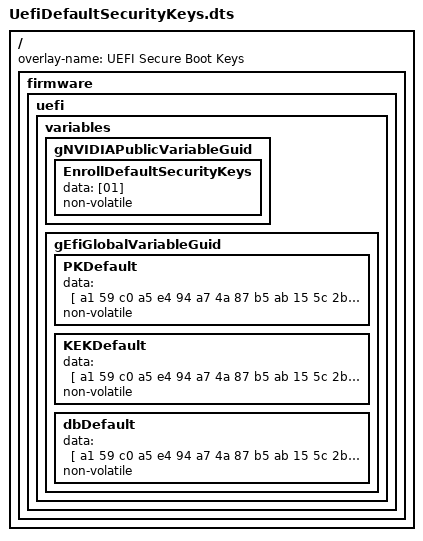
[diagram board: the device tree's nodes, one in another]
/** @file
*
*  Copyright (c) 2023, NVIDIA CORPORATION & AFFILIATES. All rights reserved.
*
*  SPDX-License-Identifier: BSD-2-Clause-Patent
*
**/
/dts-v1/;
/plugin/;
/ {
    overlay-name = "UEFI Secure Boot Keys";
    fragment@0 {
        target-path = "/";
        board_config {
            sw-modules = "uefi";
        };
        __overlay__ {
            firmware {
                uefi {
                    variables {
                        gNVIDIAPublicVariableGuid {
                            EnrollDefaultSecurityKeys {
                                data = [01];
                                non-volatile;
                            };
                        };
                        gEfiGlobalVariableGuid {
                            PKDefault {
                                data = [
 a1 59 c0 a5 e4 94 a7 4a 87 b5 ab 15 5c 2b f0 72
 45 03 00 00 00 00 00 00 29 03 00 00 7a 8a f5 48
 32 b1 61 4e b8 34 e8 10 be 6f e1 2a 30 82 03 15
 30 82 01 fd a0 03 02 01 02 02 14 2b 3d d5 c5 00
 8a cb 62 a8 bc d1 e1 d6 67 f1 09 9d 78 b3 18 30
 0d 06 09 2a 86 48 86 f7 0d 01 01 0b 05 00 30 1a
 31 18 30 16 06 03 55 04 03 0c 0f 6d 79 20 50 6c
 61 74 66 6f 72 6d 20 4b 65 79 30 1e 17 0d 32 33
 30 39 31 39 32 30 35 31 34 38 5a 17 0d 33 33 30
 39 31 36 32 30 35 31 34 38 5a 30 1a 31 18 30 16
 06 03 55 04 03 0c 0f 6d 79 20 50 6c 61 74 66 6f
 72 6d 20 4b 65 79 30 82 01 22 30 0d 06 09 2a 86
 48 86 f7 0d 01 01 01 05 00 03 82 01 0f 00 30 82
 01 0a 02 82 01 01 00 b8 79 e8 a8 e0 42 ee 26 be
 7a df 9b 87 3b b6 f8 f2 cd 36 02 a3 3a d9 23 ba
 ba f2 52 91 be f3 2a f1 0f 71 1d 7d 46 b3 04 74
 59 a1 51 f4 53 31 ed 18 a8 3c cb eb 56 ca fb f5
 d8 f0 91 c1 9a 37 0f 99 08 bd ad 8c ee de c8 8c
 e4 e7 a0 51 b3 85 06 6f e7 32 cb 68 ca dd db 16
 24 1a 8f 71 2c 3f a0 fe 41 db 8b 65 5b dd 6d 68
 bc 57 8b 59 00 53 9a 30 fe a2 a9 23 4b f4 0b ab
 7e 2d 8a d0 83 87 28 c2 e5 de 07 41 b1 c3 ed 2f
 98 f7 f1 1c c7 fb 7d 6d 19 54 96 27 36 85 5b f8
 26 37 c3 b7 4f 68 7d 4d 83 48 3e 27 61 a4 8c e9
 33 89 6f d7 a7 e6 cc 14 e3 1a f4 7d 3d 22 8d ff
 a4 14 64 24 2a 30 6d 94 dc b6 0e 99 06 8c a0 2e
 32 0b ee 63 60 92 d6 89 ce 74 a4 6d bc f8 fa 94
 f8 d7 3e 15 ea 50 35 83 37 d3 68 cd fc 5e 85 53
 bb db d8 11 a8 2c be 64 32 ab 99 8e 90 99 e8 04
 12 fe 33 1d 57 61 21 02 03 01 00 01 a3 53 30 51
 30 1d 06 03 55 1d 0e 04 16 04 14 6f 55 55 a2 58
 c7 90 6b 9c 11 bf f0 f3 10 81 12 18 0c 0c 62 30
 1f 06 03 55 1d 23 04 18 30 16 80 14 6f 55 55 a2
 58 c7 90 6b 9c 11 bf f0 f3 10 81 12 18 0c 0c 62
 30 0f 06 03 55 1d 13 01 01 ff 04 05 30 03 01 01
 ff 30 0d 06 09 2a 86 48 86 f7 0d 01 01 0b 05 00
 03 82 01 01 00 74 d7 ce 48 a0 67 06 7c 07 03 4b
 d1 d1 30 74 e7 17 76 3b 1d 89 36 88 9c c4 01 f9
 28 63 06 bc 92 ba ad 69 2f 27 46 e0 90 a3 c5 62
 29 96 d8 92 23 2f 9e 80 51 e5 22 3e f1 d0 99 18
 48 5d fc 95 20 57 da b0 d8 13 c4 58 b4 51 ed f4
 90 6d f9 41 8a b7 a6 a4 92 f7 bc d3 ec 65 0c 16
 fc 85 ed 46 dc 69 82 8e 65 0c b6 f6 0e 54 dd e1
 4b a1 c0 68 64 aa 1a 3d d1 01 d9 2d 7c 6f ac 7f
 f5 c5 01 8b 8b 51 6d b0 a7 15 4d a9 d1 72 16 86
 24 43 20 3d aa 16 25 6d a8 a1 2f 41 17 59 47 7f
 db 68 fe 4b 0f 4f dd 9c 9d 9c fc 69 5c 20 11 2a
 dd be 03 36 17 bb 4c 4d 41 57 e8 9b 7a dc b3 85
 8e 1e 51 3b c0 f8 1e ea d6 52 df 91 ce 77 a9 a6
 43 42 87 be 41 0d f0 89 1f 1e cd 1a df 10 04 0e
 c8 10 dd b5 19 61 3d 01 1d 08 22 03 55 e4 8a ae
 77 ee dc 50 df 05 53 da 57 4a b6 29 cc fd df 11
 84 0b dd 2f ea
                                ];
                                non-volatile;
                            };
                            KEKDefault {
                                data = [
 a1 59 c0 a5 e4 94 a7 4a 87 b5 ab 15 5c 2b f0 72
 4d 03 00 00 00 00 00 00 31 03 00 00 4b 3b d9 b0
 e3 95 4b 45 86 fe 99 7f d9 d6 bf 01 30 82 03 1d
 30 82 02 05 a0 03 02 01 02 02 14 2a b7 23 c1 01
 94 4d 45 ce 40 ed 71 28 7d 0d dd 45 dc ee ab 30
 0d 06 09 2a 86 48 86 f7 0d 01 01 0b 05 00 30 1e
 31 1c 30 1a 06 03 55 04 03 0c 13 6d 79 20 4b 65
 79 20 45 78 63 68 61 6e 67 65 20 4b 65 79 30 1e
 17 0d 32 33 30 39 31 39 32 30 35 32 31 30 5a 17
 0d 33 33 30 39 31 36 32 30 35 32 31 30 5a 30 1e
 31 1c 30 1a 06 03 55 04 03 0c 13 6d 79 20 4b 65
 79 20 45 78 63 68 61 6e 67 65 20 4b 65 79 30 82
 01 22 30 0d 06 09 2a 86 48 86 f7 0d 01 01 01 05
 00 03 82 01 0f 00 30 82 01 0a 02 82 01 01 00 9a
 2a a1 86 9c 96 8f fb 86 10 bd b2 54 d7 0c 23 b3
 59 64 96 f2 a3 29 bd f0 36 b8 a6 fe 1e aa a3 9d
 04 d4 69 08 76 b6 99 63 1b f9 1a 92 6d 55 6c 46
 d5 06 e3 a7 d6 be 4b d8 a9 9e 86 1c 78 c1 ba 2d
 9a 4a 29 2b a1 7b 80 92 86 9e 76 c2 1b 7c a7 33
 3c 44 c9 65 f1 40 9f 35 94 9a ec e7 de ea 60 8e
 3d 74 01 00 07 e9 6a a0 90 2e ed a7 45 66 5c 19
 16 7c 77 a0 c1 2c 87 39 2e 70 8c 25 26 1f 95 52
 5f 11 c9 9b 18 d2 02 88 2c 67 cf b2 b9 01 4c 33
 a2 73 24 5d ee 97 a1 12 37 40 05 18 f6 0a 74 de
 41 13 3d f8 7f a3 1e c5 65 f1 0f 6c 43 de d6 ee
 0c 91 87 db c7 da 1b e7 ed 87 67 ed f3 bc d9 c7
 ca 1c 8f b0 83 48 ff f6 f0 40 bc 44 cd fb 45 52
 89 ff a8 53 33 79 b3 2e 4a 3f b2 ff f3 bc 8d 92
 8b f3 8b 19 d5 cf 70 11 1b ce c0 c3 74 57 4b 6f
 5d 9a be 09 e0 0c 5d 44 c1 20 95 d8 40 69 eb 02
 03 01 00 01 a3 53 30 51 30 1d 06 03 55 1d 0e 04
 16 04 14 ea 25 0e 39 55 31 b1 db e6 e9 25 7f 73
 e2 bc fc 1d bc 4f c3 30 1f 06 03 55 1d 23 04 18
 30 16 80 14 ea 25 0e 39 55 31 b1 db e6 e9 25 7f
 73 e2 bc fc 1d bc 4f c3 30 0f 06 03 55 1d 13 01
 01 ff 04 05 30 03 01 01 ff 30 0d 06 09 2a 86 48
 86 f7 0d 01 01 0b 05 00 03 82 01 01 00 42 67 ca
 59 4d 62 d1 39 4f d8 93 c1 09 b8 9c 29 a1 1c bc
 ae 82 26 9e d5 dd 35 f6 12 47 47 2b fb 5d 0b 4d
 e8 0c 4c c9 70 b9 85 e5 81 4f 9f 71 00 70 fe 55
 1b ee 47 f7 fa 41 77 ed 58 d1 16 ac 1f 44 a3 03
 f2 47 c5 db 1d 96 fa de 01 a4 34 0f 3e 1d 4e 90
 d6 50 4d 5e 85 cb 09 7b 69 c4 7c b0 cd 78 26 00
 f0 55 78 09 c1 5d cd 8d bd ce 61 a9 db 7d da a1
 6f 6e b6 58 d9 b9 00 c0 d4 90 6f 9e ea 94 d6 17
 0e 05 1a 16 46 26 e0 10 8c 62 f5 3f c3 96 b1 d4
 37 c0 c3 e6 d4 53 10 4b a8 c1 96 41 94 d2 24 0e
 24 d3 e9 9d 58 7d df 04 18 25 e7 66 aa 91 43 50
 b1 d8 48 2c b4 69 d6 8d 6a ab 81 ab 52 2d 19 b3
 2a c7 86 f6 87 66 40 69 ad 58 60 08 0a c9 f0 8b
 eb 91 04 55 13 d8 92 00 1e 1c 8b 13 0d 9a 71 32
 c4 e4 d0 e2 3c ee d2 50 7f e4 93 4d ef ed 8f 53
 8a 7f d0 3d bf 37 4a 66 26 da 4d 6a 79
                                ];
                                non-volatile;
                            };
                            dbDefault {
                                data = [
 a1 59 c0 a5 e4 94 a7 4a 87 b5 ab 15 5c 2b f0 72
 59 03 00 00 00 00 00 00 3d 03 00 00 50 7c ee b0
 ed 19 f9 4e 95 4a 86 1f d2 57 b1 a3 30 82 03 29
 30 82 02 11 a0 03 02 01 02 02 14 78 9b c4 26 ce
 38 9a 5b 80 0d d0 3b 28 e0 c2 ef 05 cb 37 59 30
 0d 06 09 2a 86 48 86 f7 0d 01 01 0b 05 00 30 24
 31 22 30 20 06 03 55 04 03 0c 19 6d 79 20 53 69
 67 6e 61 74 75 72 65 20 44 61 74 61 62 61 73 65
 20 6b 65 79 30 1e 17 0d 32 33 30 39 31 39 32 30
 35 34 31 33 5a 17 0d 33 33 30 39 31 36 32 30 35
 34 31 33 5a 30 24 31 22 30 20 06 03 55 04 03 0c
 19 6d 79 20 53 69 67 6e 61 74 75 72 65 20 44 61
 74 61 62 61 73 65 20 6b 65 79 30 82 01 22 30 0d
 06 09 2a 86 48 86 f7 0d 01 01 01 05 00 03 82 01
 0f 00 30 82 01 0a 02 82 01 01 00 e8 e7 6f 64 1d
 b6 64 44 04 f9 46 13 67 29 f4 11 90 b3 93 28 76
 02 98 d4 4f 05 e4 51 fb e2 55 8a 93 ff 26 8b b9
 d7 20 5c 07 99 8c 24 bc e3 ee 5a ba 33 33 7b ef
 a1 14 ba 34 28 94 4b 6d 01 cb 9a 86 27 f5 03 f4
 c4 26 3e 3f 76 f4 46 71 95 f6 05 4d 52 ee f9 66
 86 46 87 6f c1 2e 06 7f ae 07 d2 71 b3 cb d7 4f
 4b 94 da 52 6b f1 a4 25 a9 1c 7d 1b 66 78 e0 d1
 3a 91 e2 fe 01 60 d6 e4 32 cb 02 1d 05 4c 23 77
 65 ce f5 f1 50 a2 33 1d 2e 81 ec 41 48 d2 9d d4
 2e 0d 9a 2f f9 e6 bb 55 a9 8b fb 70 93 fa 0a a1
 1f 76 0c 2f e8 86 46 db f6 05 b4 90 9a 0e c3 19
 96 d7 da 36 ef 41 67 b6 c8 78 b0 35 c6 8d f6 e6
 60 46 4f ee 5d 63 86 2d 98 19 52 20 8b b0 83 ea
 9e 4f 3e 73 14 ee 88 0c 44 0c 3a e0 c0 ec 0c 1f
 8c 03 88 72 b7 da 4c e1 11 8f b8 2e 14 c8 17 49
 37 74 0a f2 d7 30 c0 cb 79 0d 4d 02 03 01 00 01
 a3 53 30 51 30 1d 06 03 55 1d 0e 04 16 04 14 83
 9b 1b 1a d7 3a bf 77 ce 24 8e 0a de 3f 60 63 1c
 a4 fe d5 30 1f 06 03 55 1d 23 04 18 30 16 80 14
 83 9b 1b 1a d7 3a bf 77 ce 24 8e 0a de 3f 60 63
 1c a4 fe d5 30 0f 06 03 55 1d 13 01 01 ff 04 05
 30 03 01 01 ff 30 0d 06 09 2a 86 48 86 f7 0d 01
 01 0b 05 00 03 82 01 01 00 88 e2 bd d5 2e c3 f6
 ec 08 8a 59 f8 0b ff f6 73 9f e0 3c 68 d0 8b 72
 04 a4 1c c8 4c 71 f4 c7 5c 5d db 90 a4 82 89 2e
 63 0c 81 b6 0b 17 d0 03 a1 82 b4 b2 20 c6 f5 ab
 1f 87 bb bf 21 86 b0 e9 08 cf c1 5e cf d2 1b 94
 aa ba 76 d0 96 71 8d 50 9a 01 35 62 2f 81 41 5e
 c0 c6 1f bf 64 c1 d2 2a 3d 03 16 e0 44 0b 9f df
 4a 9f bb 1d f5 03 db 01 c8 0b 33 ed d0 6e 8e f2
 c0 df 02 93 70 08 92 4d 17 3e cb 99 35 4b 23 18
 e7 7b f2 08 c7 a7 ea ec 8f 68 9d b2 97 c6 6c cc
 4c b1 6f c2 75 91 3f c9 3e 06 62 f3 3e 55 f7 ec
 58 1a 5d 3e 34 ba 6f a1 7b b2 6f cb b3 6a b0 cf
 c4 29 35 b0 fd be dd c8 d7 3b 3f 57 4b 65 34 7c
 1b 96 bf a0 9f a1 7c c8 e5 f7 04 fa 9b ee 63 7e
 c9 3c 1e 62 6d 0a 62 2b 64 8a 86 87 21 02 e0 8a
 e6 4d 64 57 25 cb 76 32 fd 49 a4 46 f1 bf ea c6
 ed 8f 54 cd 73 38 b0 c8 a3
                                ];
                                non-volatile;
                            };
                        };
                    };
                };
            };
        };
    };
};
